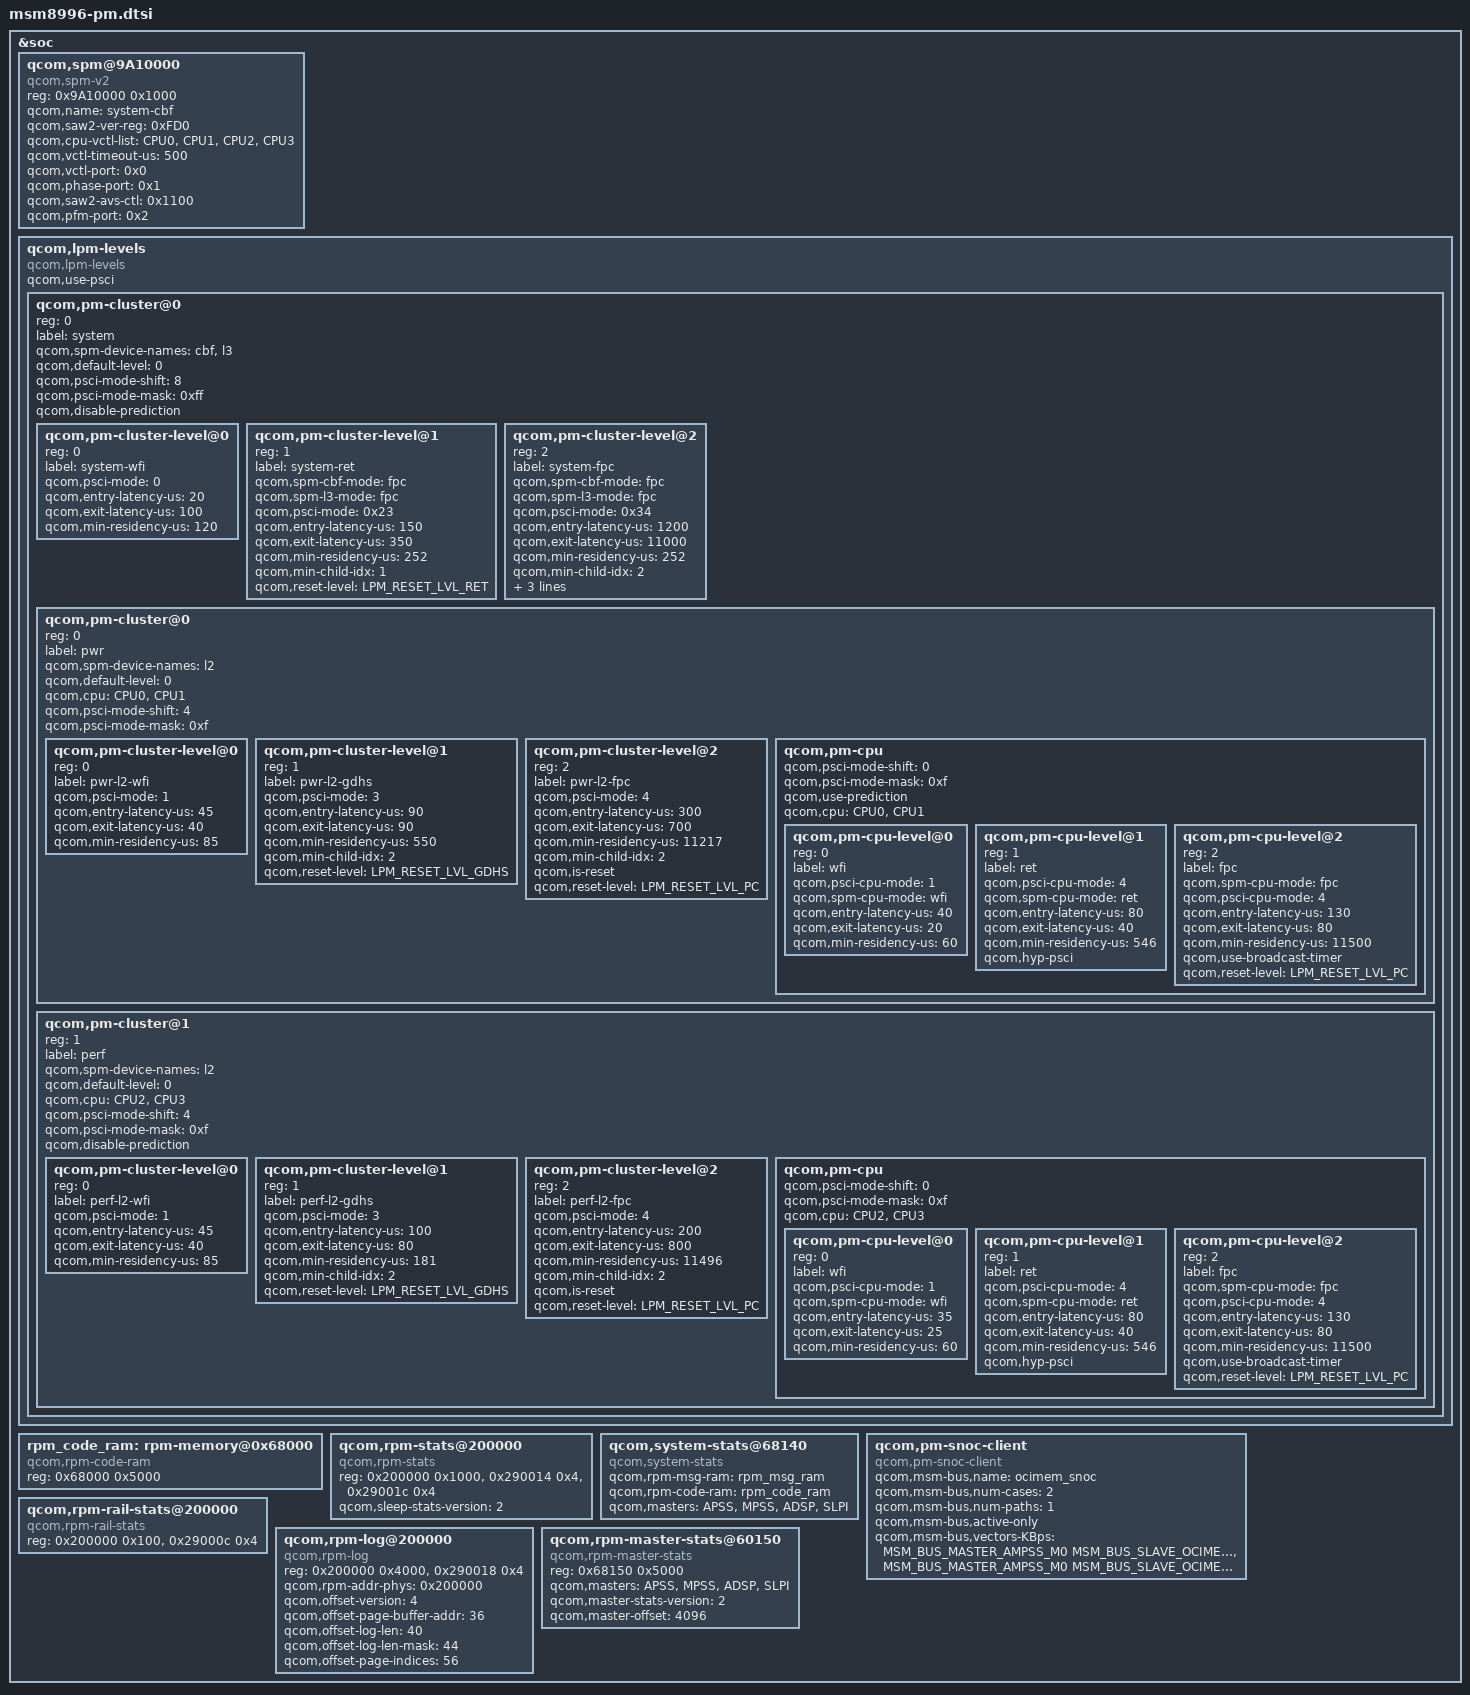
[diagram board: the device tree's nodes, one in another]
/* Copyright (c) 2015-2017, The Linux Foundation. All rights reserved.
 *
 * This program is free software; you can redistribute it and/or modify
 * it under the terms of the GNU General Public License version 2 and
 * only version 2 as published by the Free Software Foundation.
 *
 * This program is distributed in the hope that it will be useful,
 * but WITHOUT ANY WARRANTY; without even the implied warranty of
 * MERCHANTABILITY or FITNESS FOR A PARTICULAR PURPOSE.  See the
 * GNU General Public License for more details.
 */

#include <dt-bindings/interrupt-controller/arm-gic.h>
#include <dt-bindings/msm/pm.h>

&soc {
	qcom,spm@9A10000 {
		compatible = "qcom,spm-v2";
		#address-cells = <1>;
		#size-cells = <1>;
		reg = <0x9A10000 0x1000>;
		qcom,name = "system-cbf"; /* CBF SAW */
		qcom,saw2-ver-reg = <0xFD0>;
		qcom,cpu-vctl-list = <&CPU0 &CPU1 &CPU2 &CPU3>;
		qcom,vctl-timeout-us = <500>;
		qcom,vctl-port = <0x0>;
		qcom,phase-port = <0x1>;
		qcom,saw2-avs-ctl = <0x1100>;
		qcom,pfm-port = <0x2>;
	};

	qcom,lpm-levels {
		compatible = "qcom,lpm-levels";
		qcom,use-psci;
		#address-cells = <1>;
		#size-cells = <0>;

		qcom,pm-cluster@0 {
			reg = <0>;
			#address-cells = <1>;
			#size-cells = <0>;
			label = "system";
			qcom,spm-device-names = "cbf", "l3";
			qcom,default-level = <0>;
			qcom,psci-mode-shift = <8>;
			qcom,psci-mode-mask = <0xff>;
			qcom,disable-prediction;

			qcom,pm-cluster-level@0{
				reg = <0>;
				label = "system-wfi";
				qcom,psci-mode = <0>;
				qcom,entry-latency-us = <20>;
				qcom,exit-latency-us = <100>;
				qcom,min-residency-us = <120>;
			};
			qcom,pm-cluster-level@1{ /* E3-M2 */
				reg = <1>;
				label = "system-ret";
				qcom,spm-cbf-mode = "fpc";
				qcom,spm-l3-mode = "fpc";
				qcom,psci-mode = <0x23>;
				/* TODO: WARNING: time_overhead - last_exit_latency <= 0
				 * Using safe value time_overhead; please recalculate */
				qcom,entry-latency-us = <150>;
				qcom,exit-latency-us = <350>;
				qcom,min-residency-us = <252>;
				qcom,min-child-idx = <1>;
				qcom,reset-level = <LPM_RESET_LVL_RET>;
			};
			qcom,pm-cluster-level@2{ /* E4-M3 */
				reg = <2>;
				label = "system-fpc";
				qcom,spm-cbf-mode = "fpc";
				qcom,spm-l3-mode = "fpc";
				qcom,psci-mode = <0x34>;
				/* TODO: WARNING: time_overhead - last_exit_latency <= 0
				 * Using safe value time_overhead; please recalculate */
				qcom,entry-latency-us = <1200>;
				qcom,exit-latency-us = <11000>;
				qcom,min-residency-us = <252>;
				qcom,min-child-idx = <2>;
				qcom,notify-rpm;
				qcom,is-reset;
				qcom,reset-level = <LPM_RESET_LVL_PC>;
			};

			qcom,pm-cluster@0{
				reg = <0>;
				#address-cells = <1>;
				#size-cells = <0>;
				label = "pwr";
				qcom,spm-device-names = "l2";
				qcom,default-level=<0>;
				qcom,cpu = <&CPU0 &CPU1>;
				qcom,psci-mode-shift = <4>;
				qcom,psci-mode-mask = <0xf>;

				qcom,pm-cluster-level@0{ /* D1 */
					reg = <0>;
					label = "pwr-l2-wfi";
					qcom,psci-mode = <1>;
					qcom,entry-latency-us = <45>;
					qcom,exit-latency-us = <40>;
					qcom,min-residency-us = <85>;
				};

				qcom,pm-cluster-level@1{ /* D3 */
					reg = <1>;
					label = "pwr-l2-gdhs";
					qcom,psci-mode = <3>;
					qcom,entry-latency-us = <90>;
					qcom,exit-latency-us = <90>;
					qcom,min-residency-us = <550>;
					qcom,min-child-idx = <2>;
					qcom,reset-level = <LPM_RESET_LVL_GDHS>;
				};

				qcom,pm-cluster-level@2{ /* D4 */
					reg = <2>;
					label = "pwr-l2-fpc";
					qcom,psci-mode = <4>;
					qcom,entry-latency-us = <300>;
					qcom,exit-latency-us = <700>;
					qcom,min-residency-us = <11217>;
					qcom,min-child-idx = <2>;
					qcom,is-reset;
					qcom,reset-level = <LPM_RESET_LVL_PC>;
				};

				qcom,pm-cpu {
					#address-cells = <1>;
					#size-cells = <0>;
					qcom,psci-mode-shift = <0>;
					qcom,psci-mode-mask = <0xf>;
					qcom,use-prediction;
					qcom,cpu = <&CPU0 &CPU1>;

					qcom,pm-cpu-level@0 { /* C1 */
						reg = <0>;
						label = "wfi";
						qcom,psci-cpu-mode = <1>;
						qcom,spm-cpu-mode = "wfi";
						qcom,entry-latency-us = <40>;
						qcom,exit-latency-us = <20>;
						qcom,min-residency-us = <60>;
					};

					qcom,pm-cpu-level@1 {  /* C4 */
						reg = <1>;
						label = "ret";
						qcom,psci-cpu-mode = <4>;
						qcom,spm-cpu-mode = "ret";
						qcom,entry-latency-us = <80>;
						qcom,exit-latency-us = <40>;
						qcom,min-residency-us = <546>;
						qcom,hyp-psci;
					};

					qcom,pm-cpu-level@2 {  /* C4 */
						reg = <2>;
						label = "fpc";
						qcom,spm-cpu-mode = "fpc";
						qcom,psci-cpu-mode = <4>;
						qcom,entry-latency-us = <130>;
						qcom,exit-latency-us = <80>;
						qcom,min-residency-us = <11500>;
						qcom,use-broadcast-timer;
						qcom,reset-level =
							<LPM_RESET_LVL_PC>;
					};
				};
			};

			qcom,pm-cluster@1{
				reg = <1>;
				#address-cells = <1>;
				#size-cells = <0>;
				label = "perf";
				qcom,spm-device-names = "l2";
				qcom,default-level=<0>;
				qcom,cpu = <&CPU2 &CPU3>;
				qcom,psci-mode-shift = <4>;
				qcom,psci-mode-mask = <0xf>;
				qcom,disable-prediction;

				qcom,pm-cluster-level@0{  /* D1 */
					reg = <0>;
					label = "perf-l2-wfi";
					qcom,psci-mode = <1>;
					qcom,entry-latency-us = <45>;
					qcom,exit-latency-us = <40>;
					qcom,min-residency-us = <85>;
				};

				qcom,pm-cluster-level@1{ /* D3 */
					reg = <1>;
					label = "perf-l2-gdhs";
					qcom,psci-mode = <3>;
					qcom,entry-latency-us = <100>;
					qcom,exit-latency-us = <80>;
					qcom,min-residency-us = <181>;
					qcom,min-child-idx = <2>;
					qcom,reset-level =
						<LPM_RESET_LVL_GDHS>;
				};

				qcom,pm-cluster-level@2{ /* D4 */
					reg = <2>;
					label = "perf-l2-fpc";
					qcom,psci-mode = <4>;
					qcom,entry-latency-us = <200>;
					qcom,exit-latency-us = <800>;
					qcom,min-residency-us = <11496>;
					qcom,min-child-idx = <2>;
					qcom,is-reset;
					qcom,reset-level =
						<LPM_RESET_LVL_PC>;
				};

				qcom,pm-cpu {
					#address-cells = <1>;
					#size-cells = <0>;
					qcom,psci-mode-shift = <0>;
					qcom,psci-mode-mask = <0xf>;
					qcom,cpu = <&CPU2 &CPU3>;

					qcom,pm-cpu-level@0 { /* C1 */
						reg = <0>;
						label = "wfi";
						qcom,psci-cpu-mode = <1>;
						qcom,spm-cpu-mode = "wfi";
						qcom,entry-latency-us = <35>;
						qcom,exit-latency-us = <25>;
						qcom,min-residency-us = <60>;
					};

					qcom,pm-cpu-level@1 {  /* C4 */
						reg = <1>;
						label = "ret";
						qcom,psci-cpu-mode = <4>;
						qcom,spm-cpu-mode = "ret";
						qcom,entry-latency-us = <80>;
						qcom,exit-latency-us = <40>;
						qcom,min-residency-us = <546>;
						qcom,hyp-psci;
					};

					qcom,pm-cpu-level@2 {  /* C4 */
						reg = <2>;
						label = "fpc";
						qcom,spm-cpu-mode = "fpc";
						qcom,psci-cpu-mode = <4>;
						qcom,entry-latency-us = <130>;
						qcom,exit-latency-us = <80>;
						qcom,min-residency-us = <11500>;
						qcom,use-broadcast-timer;
						qcom,reset-level =
							<LPM_RESET_LVL_PC>;
					};
				};
			};
		};
	};

	rpm_code_ram: rpm-memory@0x68000 {
		compatible = "qcom,rpm-code-ram";
		reg = <0x68000 0x5000>;
	};

	qcom,rpm-stats@200000 {
		compatible = "qcom,rpm-stats";
		reg = <0x200000 0x1000>,
			<0x290014 0x4>,
			<0x29001c 0x4>;
		reg-names = "phys_addr_base",
			    "offset_addr",
			    "heap_phys_addrbase";
		qcom,sleep-stats-version = <2>;
	};

	qcom,system-stats@68140 {
		compatible = "qcom,system-stats";
		qcom,rpm-msg-ram = <&rpm_msg_ram>;
		qcom,rpm-code-ram = <&rpm_code_ram>;
		qcom,masters = "APSS", "MPSS", "ADSP", "SLPI";
	};

	qcom,pm-snoc-client {
		compatible = "qcom,pm-snoc-client";
		qcom,msm-bus,name = "ocimem_snoc";
		qcom,msm-bus,num-cases = <2>;
		qcom,msm-bus,num-paths = <1>;
		qcom,msm-bus,active-only;
		qcom,msm-bus,vectors-KBps =
			<MSM_BUS_MASTER_AMPSS_M0 MSM_BUS_SLAVE_OCIMEM 0 0>,
			<MSM_BUS_MASTER_AMPSS_M0 MSM_BUS_SLAVE_OCIMEM 0 800000>;
	};

	qcom,rpm-rail-stats@200000 {
		compatible = "qcom,rpm-rail-stats";
		reg = <0x200000 0x100>,
			<0x29000c 0x4>;
		reg-names = "phys_addr_base",
			    "offset_addr";
	};

	qcom,rpm-log@200000 {
		compatible = "qcom,rpm-log";
		reg = <0x200000 0x4000>,
			<0x290018 0x4>;
		qcom,rpm-addr-phys = <0x200000>;
		qcom,offset-version = <4>;
		qcom,offset-page-buffer-addr = <36>;
		qcom,offset-log-len = <40>;
		qcom,offset-log-len-mask = <44>;
		qcom,offset-page-indices = <56>;
	};

	qcom,rpm-master-stats@60150 {
		compatible = "qcom,rpm-master-stats";
		reg = <0x68150 0x5000>;
		qcom,masters = "APSS", "MPSS", "ADSP", "SLPI";
		qcom,master-stats-version = <2>;
		qcom,master-offset = <4096>;
	};

};
